AUTOSAR XML (schema 314)
package /ComponentType
  internal behavior Sa_OvrVoltMon_InternalBehavior: component=Sa_OvrVoltMon
    timing event TMT_OvrVoltMon_Per1: mode-dependency=dependent-on-mode=[SystemState.Mode.DISABLE, SystemState.Mode.OFF], start-on-event=OvrVoltMon_Per1, period=0.002
    port-api-options:
      enable-take-address=false, indirect-api=false, port=NxtrDiagMgr
      enable-take-address=false, indirect-api=false, port=phyOvrVoltFdbk
      enable-take-address=false, indirect-api=false, port=PwrDiscBTestStart
      enable-take-address=false, indirect-api=false, port=SystemState
    runnable OvrVoltMon_Per1
      data read access READ_PwrDiscBTestStart_Cnt_lgc: data-element=PwrDiscBTestStart.Cnt_lgc
      sync call SC_NxtrDiagMgr_SetNTCStatus: operation=NxtrDiagMgr.SetNTCStatus, timeout=0
      sync call SC_phyOvrVoltFdbk_OP_GET: operation=phyOvrVoltFdbk.OP_GET, timeout=0
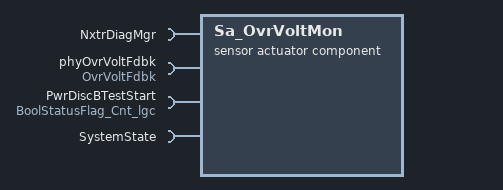
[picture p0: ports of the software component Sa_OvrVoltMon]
  sensor actuator software component type Sa_OvrVoltMon
    4 x require port:
      NxtrDiagMgr: required-com-specs=[GetNTCActive, GetNTCFailed, GetNTCStatus, SetNTCStatus], required-interface=NxtrDiagMgr
      phyOvrVoltFdbk: client-com-spec=OP_GET, required-interface=OvrVoltFdbk
      PwrDiscBTestStart: unqueued-receiver-com-spec{data-element=Cnt_lgc, init-value=D_FALSE_CNT_LGC}, required-interface=BoolStatusFlag_Cnt_lgc
      SystemState: required-interface=SystemState
  swc implementation Sa_OvrVoltMon_Implementation: behavior=Sa_OvrVoltMon_InternalBehavior
    code-descriptors:
      code Code: type=SRC
